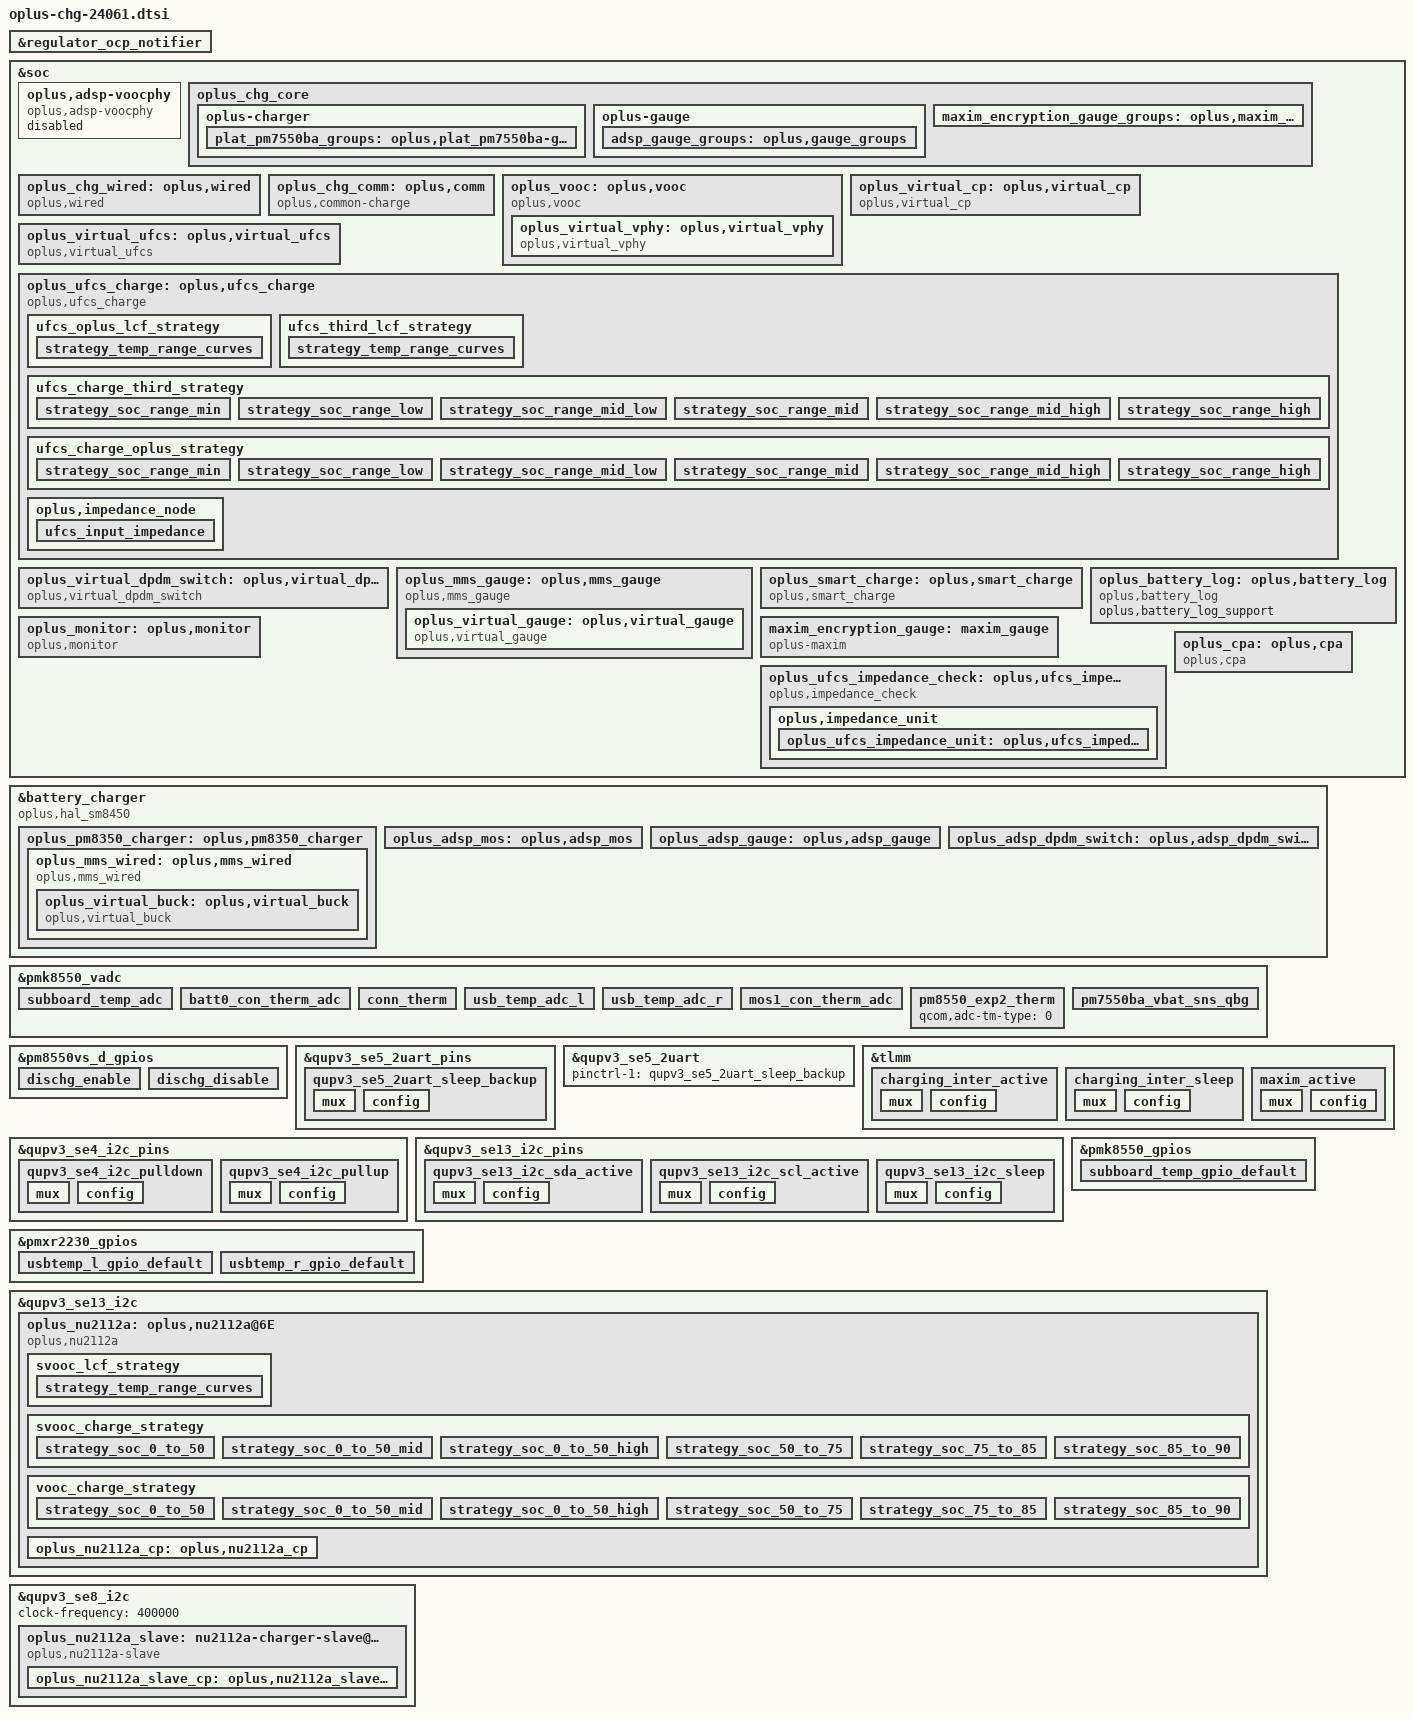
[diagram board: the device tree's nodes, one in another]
#include "oplus_chg.h"

&regulator_ocp_notifier {
	periph-1cb-supply = <0>;
	periph-1cc-supply = <0>;
	periph-1cd-supply = <0>;
	periph-4c1-supply = <0>;
	periph-4c3-supply = <0>;
};

&soc {
	oplus,adsp-voocphy {
		status = "disabled";
		compatible = "oplus,adsp-voocphy";
	};

	oplus_chg_core {
		oplus,chg_framework_v2;
		oplus,smart_charging_screenoff;
		oplus,chg_spec_version = <OPLUS_CHG_SPEC_VER_V3P7>;

		oplus-charger {
			plat_pm7550ba_groups: oplus,plat_pm7550ba-groups {
				functions = <
					OPLUS_IC_FUNC_INIT
					OPLUS_IC_FUNC_EXIT
					OPLUS_IC_FUNC_REG_DUMP
					OPLUS_IC_FUNC_SMT_TEST
					OPLUS_IC_FUNC_BUCK_INPUT_PRESENT
					OPLUS_IC_FUNC_BUCK_INPUT_SUSPEND
					OPLUS_IC_FUNC_BUCK_INPUT_IS_SUSPEND
					OPLUS_IC_FUNC_BUCK_OUTPUT_SUSPEND
					OPLUS_IC_FUNC_BUCK_OUTPUT_IS_SUSPEND
					OPLUS_IC_FUNC_BUCK_GET_CC_ORIENTATION
					OPLUS_IC_FUNC_BUCK_GET_CHARGER_TYPE
					OPLUS_IC_FUNC_BUCK_RERUN_BC12
					OPLUS_IC_FUNC_BUCK_QC_DETECT_ENABLE
					OPLUS_IC_FUNC_BUCK_SHIPMODE_ENABLE
					OPLUS_IC_FUNC_BUCK_SET_QC_CONFIG
					OPLUS_IC_FUNC_BUCK_SET_PD_CONFIG
					OPLUS_IC_FUNC_BACKUP_SOC
					OPLUS_IC_FUNC_GET_SHUTDOWN_SOC
					OPLUS_IC_FUNC_GET_TYPEC_MODE
					OPLUS_IC_FUNC_BUCK_SET_ICL
					OPLUS_IC_FUNC_BUCK_GET_ICL
					OPLUS_IC_FUNC_BUCK_SET_FCC
					OPLUS_IC_FUNC_BUCK_SET_FV
					OPLUS_IC_FUNC_BUCK_SET_ITERM
					OPLUS_IC_FUNC_BUCK_SET_RECHG_VOL
					OPLUS_IC_FUNC_BUCK_GET_INPUT_CURR
					OPLUS_IC_FUNC_BUCK_GET_INPUT_VOL
					OPLUS_IC_FUNC_GET_CHARGER_CYCLE
					OPLUS_IC_FUNC_OTG_BOOST_ENABLE
					OPLUS_IC_FUNC_BUCK_GET_VBUS_COLLAPSE_STATUS
					OPLUS_IC_FUNC_GET_OTG_ENABLE
					OPLUS_IC_FUNC_SET_OTG_SWITCH_STATUS
					OPLUS_IC_FUNC_GET_OTG_SWITCH_STATUS
					OPLUS_IC_FUNC_GET_OTG_ONLINE_STATUS
					OPLUS_IC_FUNC_BUCK_GET_HW_DETECT
					OPLUS_IC_FUNC_VOOCPHY_SET_MATCH_TEMP
					OPLUS_IC_FUNC_IS_OPLUS_SVID
					OPLUS_IC_FUNC_BUCK_GET_USB_BTB_TEMP
					OPLUS_IC_FUNC_BUCK_GET_BATT_BTB_TEMP
					OPLUS_IC_FUNC_SET_TYPEC_MODE
					OPLUS_IC_FUNC_GET_TYPEC_ROLE
				>;
				virqs = <
					OPLUS_IC_VIRQ_ERR
					OPLUS_IC_VIRQ_CC_DETECT
					OPLUS_IC_VIRQ_PLUGIN
					OPLUS_IC_VIRQ_CC_CHANGED
					OPLUS_IC_VIRQ_CHG_TYPE_CHANGE
					OPLUS_IC_VIRQ_SVID
					OPLUS_IC_VIRQ_OTG_ENABLE
				>;
			};
		};

		oplus-gauge {
			adsp_gauge_groups: oplus,gauge_groups {
				functions = <
					OPLUS_IC_FUNC_INIT
					OPLUS_IC_FUNC_EXIT
					OPLUS_IC_FUNC_REG_DUMP
					OPLUS_IC_FUNC_SMT_TEST
					OPLUS_IC_FUNC_GAUGE_GET_BATT_VOL
					OPLUS_IC_FUNC_GAUGE_GET_BATT_MAX
					OPLUS_IC_FUNC_GAUGE_GET_BATT_MIN
					OPLUS_IC_FUNC_GAUGE_GET_BATT_CURR
					OPLUS_IC_FUNC_GAUGE_GET_BATT_TEMP
					OPLUS_IC_FUNC_GAUGE_GET_BATT_SOC
					OPLUS_IC_FUNC_GAUGE_GET_BATT_FCC
					OPLUS_IC_FUNC_GAUGE_GET_BATT_CC
					OPLUS_IC_FUNC_GAUGE_GET_BATT_RM
					OPLUS_IC_FUNC_GAUGE_GET_BATT_SOH
					OPLUS_IC_FUNC_GAUGE_GET_BATT_HMAC
					OPLUS_IC_FUNC_GAUGE_SET_BATT_FULL
					OPLUS_IC_FUNC_GAUGE_UPDATE_DOD0
					OPLUS_IC_FUNC_GAUGE_UPDATE_SOC_SMOOTH
					OPLUS_IC_FUNC_GAUGE_GET_CB_STATUS
					OPLUS_IC_FUNC_GAUGE_GET_BATT_NUM
					OPLUS_IC_FUNC_GAUGE_GET_DEVICE_TYPE
					OPLUS_IC_FUNC_GAUGE_GET_DEVICE_TYPE_FOR_VOOC
					OPLUS_IC_FUNC_GAUGE_GET_BATT_FCC
					OPLUS_IC_FUNC_GAUGE_UPDATE
					OPLUS_IC_FUNC_GAUGE_IS_SUSPEND
					OPLUS_IC_FUNC_GAUGE_GET_SUBBOARD_TEMP
					OPLUS_IC_FUNC_GAUGE_GET_BCC_PARMS
					OPLUS_IC_FUNC_GAUGE_GET_DEVICE_TYPE_FOR_BCC
					OPLUS_IC_FUNC_GAUGE_GET_DOD0
					OPLUS_IC_FUNC_GAUGE_GET_DOD0_PASSED_Q
					OPLUS_IC_FUNC_GAUGE_GET_QMAX
					OPLUS_IC_FUNC_GAUGE_GET_QMAX_PASSED_Q
				>;
				virqs = <
					OPLUS_IC_VIRQ_ERR
					OPLUS_IC_VIRQ_OFFLINE
					OPLUS_IC_VIRQ_RESUME
				>;
			};
		};

		maxim_encryption_gauge_groups: oplus,maxim_encryption_gauge_groups {
			functions = <
				OPLUS_IC_FUNC_INIT
				OPLUS_IC_FUNC_EXIT
				OPLUS_IC_FUNC_GAUGE_GET_BATT_AUTH
			>;
			virqs = <
				OPLUS_IC_VIRQ_ERR
			>;
		};
	};

	oplus_chg_wired: oplus,wired {
		compatible = "oplus,wired";
		oplus,vooc-support;

		oplus_spec,vbatt_pdqc_to_9v_thr = <5000>;
		oplus_spec,pd-iclmax-ma = <1500>;
		oplus_spec,qc-iclmax-ma = <1500>;
		oplus_spec,non-standard-ibatmax-ma = <1000>;
		oplus_spec,input-power-mw = <
			2500		/* OPLUS_WIRED_CHG_MODE_UNKNOWN */
			2500		/* OPLUS_WIRED_CHG_MODE_SDP */
			7500		/* OPLUS_WIRED_CHG_MODE_CDP */
			10000		/* OPLUS_WIRED_CHG_MODE_DCP */
			30000		/* OPLUS_WIRED_CHG_MODE_VOOC */
			13500		/* OPLUS_WIRED_CHG_MODE_QC */
			13500		/* OPLUS_WIRED_CHG_MODE_PD */
		>;
		oplus_spec,led_on-fccmax-ma = <0 1340 4000 4000 4000 4000 4000 1000 0>;
		oplus_spec,fccmax-ma-lv = <
			0 1555 2200 2200 2200 2200 2200 2200 0	/* OPLUS_WIRED_CHG_MODE_UNKNOWN */
			0 600  600  600  600  600  600  600  0	/* OPLUS_WIRED_CHG_MODE_SDP */
			0 1555 1600 1600 1600 1600 1600 1600 0	/* OPLUS_WIRED_CHG_MODE_CDP */
			0 1555 2200 2200 2200 2200 2200 2200 0	/* OPLUS_WIRED_CHG_MODE_DCP */
			0 1340 3600 3600 3600 3600 3600 2948 0	/* OPLUS_WIRED_CHG_MODE_VOOC */
			0 1555 3300 3300 3300 3300 3300 3300 0	/* OPLUS_WIRED_CHG_MODE_QC */
			0 1555 3300 3300 3300 3300 3300 3300 0	/* OPLUS_WIRED_CHG_MODE_PD */
		>;
		oplus_spec,fccmax-ma-hv = <
			0 1555 2200 2200 2200 2200 2200 2200 0	/* OPLUS_WIRED_CHG_MODE_UNKNOWN */
			0 600  600  600  600  600  600  600  0	/* OPLUS_WIRED_CHG_MODE_SDP */
			0 1555 1600 1600 1600 1600 1600 1600 0	/* OPLUS_WIRED_CHG_MODE_CDP */
			0 1555 2200 2200 2200 2200 2200 2200 0	/* OPLUS_WIRED_CHG_MODE_DCP */
			0 1340 3600 3600 3600 3600 3600 2948 0	/* OPLUS_WIRED_CHG_MODE_VOOC */
			0 1555 3300 3300 3300 3300 3300 3300 0	/* OPLUS_WIRED_CHG_MODE_QC */
			0 1555 3300 3300 3300 3300 3300 3300 0	/* OPLUS_WIRED_CHG_MODE_PD */
		>;

		oplus_spec,cool_down_pdqc_vol_mv = <9000 9000 9000>;
		oplus_spec,cool_down_pdqc_curr_ma = <1200 1500 1500>;
		oplus_spec,cool_down_vooc_curr_ma = <1200 1500 2000 2500 3000 3000>;
		oplus_spec,cool_down_normal_curr_ma = <1200 1500 2000>;

		oplus_spec,vbus_ov_thr_mv = <11000 11000>;
		oplus_spec,vbus_uv_thr_mv = <4300 4300>;

		/* first data is strategy used temp type */
		oplus,vooc_strategy_name = "cgcl";
		oplus,vooc_strategy_data = <OPLUS_STRATEGY_USE_BATT_TEMP
					    0   350 3000 1 0
					    330 370 3000 2 0
					    350 440 2200 2 1>;
	};

	oplus_chg_comm: oplus,comm {
		compatible = "oplus,common-charge";
		oplus_spec,batt-them-thr = <(-100) 0 50 120 160 350 450 530>;
		oplus_spec,iterm-ma = <144>;
		oplus_spec,fv-mv = <4470 4470 4470 4470 4470 4470 4470 4130 4130>;
		oplus_spec,sw-fv-mv = <4420 4420 4420 4420 4420 4420 4420 4080 4080>;
		oplus_spec,hw-fv-inc-mv = <0 18 18 18 18 18 18 18 0>;
		oplus_spec,sw-over-fv-mv = <4480 4480 4480 4480 4480 4480 4480 4140 4140>;
		oplus_spec,sw-over-fv-dec-mv = <8>;
		oplus_spec,non-standard-sw-fv-mv = <3930>;
		oplus_spec,non-standard-fv-mv = <3980>;
		oplus_spec,non-standard-hw-fv-inc-mv = <18>;
		oplus_spec,non-standard-sw-over-fv-mv = <3990>;
		oplus_spec,non-standard-vbatdet-mv = <3680>;
		oplus_spec,wired-vbatdet-mv = <0 4170 4270 4370 4370 4370 4370 4030 0>;
		/* oplus_spec,wls-vbatdet-mv = <0 3675 4235 4370 4370 4370 4030 0>; */
		oplus_spec,fcc-gear-thr-mv = <4180>;
		oplus_spec,vbatt-ov-thr-mv = <4600>;

		oplus_spec,full_pre_ffc_judge;
		oplus_spec,full-pre-ffc-mv = <4465>;
		oplus_spec,ffc-temp-thr = <120 200 350 400>;
		oplus_spec,wired-ffc-step-max = <2>;
		oplus_spec,wired-ffc-fv-mv = <4590 4590>;
		oplus_spec,wired-ffc-fv-cutoff-mv = <4565 4565 4565 4565 4565 4565>;

		oplus_spec,removed_bat_decidegc = <390>;

		oplus_spec,wired-ffc-fcc-ma = <1500 1500 1700
					       700  700  700>;
		oplus_spec,wired-ffc-fcc-cutoff-ma = <800 1100 1500
						      800 1100 1500>;

		/* 2s battery */
		oplus_spec,wired-aging-ffc-version = <AGING_FFC_V1>;
		oplus_spec,wired-aging-ffc-offset-mv = <15 30
							10 20>;
		oplus_spec,wired-aging-ffc-cycle-thr = <500 1000>;

		oplus_spec,wls-ffc-step-max = <2>;
		oplus_spec,wls-ffc-fv-mv = <4500 4500>;
		oplus_spec,wls-ffc-fv-cutoff-mv = <4445 4435>;
		oplus_spec,wls-ffc-icl-ma = <800 800
					     550  550>;
		oplus_spec,wls-ffc-fcc-ma = <550 550
					     350 350>;
		oplus_spec,wls-ffc-fcc-cutoff-ma = <400 400
						    200 200>;
		oplus_spec,vbat_uv_thr_mv = <3300>;
		oplus_spec,vbat_charging_uv_thr_mv = <3200>;

		/*If use subboard NTC as battery temp, config it as 20, otherwise 0 */
		oplus_spec,tbatt_power_off_cali_temp = <20>;
		oplus,vooc_show_ui_soc_decimal;
		oplus,ui_soc_decimal_speedmin = <20>;

		oplus,gauge_stuck_jump_support;
		oplus,gauge_stuck_threshold = <15>;
		oplus,gauge_stuck_time = <50>;

		oplus,smooth_switch;
		oplus,reserve_chg_soc = <3>;
		oplus,reserve_dis_soc = <3>;
	};

	oplus_vooc: oplus,vooc {
		compatible = "oplus,vooc";
		oplus,vooc_ic = <&oplus_virtual_vphy>;

		oplus_spec,vooc_soc_range = <50 75 85>;
		oplus_spec,vooc_temp_range = <50 120 180 350 450>;

		oplus,vooc_data_width = <7>;
		oplus,vooc_curr_max = <CP_CURR_LIMIT_7BIT_15_0A>;  /* 80W: 11V 7.3A(IBUS *2) */
		oplus,vooc_project = <7>;  /* 80W, 11V 7.3A */
		oplus,vooc_curr_table_type = <VOOC_CP_CURR_TABLE>;
		oplus,vooc_power_max_w = <80>;
		oplus,voocphy_support = <3>; /* AP_DUAL_CP_VOOCPHY */
		oplus,support_fake_vooc_check;
		oplus,subboard_ntc_abnormal_current = <4000>;

		oplus,smart_chg_bcc_support;

		oplus,abnormal_adapter_current = <CP_CURR_LIMIT_7BIT_15_0A CP_CURR_LIMIT_7BIT_15_0A
						CP_CURR_LIMIT_7BIT_12_6A CP_CURR_LIMIT_7BIT_12_6A
						CP_CURR_LIMIT_7BIT_10_0A CP_CURR_LIMIT_7BIT_10_0A
						CP_CURR_LIMIT_7BIT_8_0A CP_CURR_LIMIT_7BIT_8_0A
						CP_CURR_LIMIT_7BIT_6_0A CP_CURR_LIMIT_7BIT_6_0A>;

		oplus,abnormal_over_80w_adapter_current = <CP_CURR_LIMIT_7BIT_15_0A CP_CURR_LIMIT_7BIT_15_0A
						CP_CURR_LIMIT_7BIT_14_0A CP_CURR_LIMIT_7BIT_14_0A
						CP_CURR_LIMIT_7BIT_12_0A CP_CURR_LIMIT_7BIT_12_0A
						CP_CURR_LIMIT_7BIT_10_0A CP_CURR_LIMIT_7BIT_10_0A
						CP_CURR_LIMIT_7BIT_8_0A  CP_CURR_LIMIT_7BIT_8_0A
						CP_CURR_LIMIT_7BIT_6_0A  CP_CURR_LIMIT_7BIT_6_0A
						CP_CURR_LIMIT_7BIT_4_0A CP_CURR_LIMIT_7BIT_4_0A>;

		/* first data is strategy used temp type */
		oplus,general_strategy_name = "cgcl";
		oplus,general_strategy_data = < OPLUS_STRATEGY_USE_SHELL_TEMP
						0   385 CP_CURR_LIMIT_7BIT_15_0A 1 0
						375 395 CP_CURR_LIMIT_7BIT_12_6A 2 0
						385 420 CP_CURR_LIMIT_7BIT_8_0A 3 1
						410 440 CP_CURR_LIMIT_7BIT_6_0A 3 2 >;

		oplus_virtual_vphy: oplus,virtual_vphy {
			compatible = "oplus,virtual_vphy";
			oplus,vphy_ic = <&oplus_nu2112a>;
			oplus,dpdm_switch_ic = <&oplus_virtual_dpdm_switch>;

			oplus,ic_type = <OPLUS_CHG_IC_VIRTUAL_VPHY>;
			oplus,ic_index = <0>;
		};
	};

	oplus_virtual_cp: oplus,virtual_cp {
		compatible = "oplus,virtual_cp";

		oplus,ic_type = <OPLUS_CHG_IC_VIRTUAL_CP>;
		oplus,ic_index = <0>;

		oplus,cp_ic = <&oplus_nu2112a_cp &oplus_nu2112a_slave_cp>;
		oplus,input_curr_max_ma = <3000 0>;

		oplus,cp_ic_connect = <OPLUS_CHG_IC_CONNECT_PARALLEL>;
		oplus,main_cp = <0>;

		oplus,reg_proc_node;
	};

	oplus_virtual_ufcs: oplus,virtual_ufcs {
		compatible = "oplus,virtual_ufcs";

		oplus,ic_type = <OPLUS_CHG_IC_VIRTUAL_UFCS>;
		oplus,ic_index = <0>;
	};

	oplus_ufcs_charge: oplus,ufcs_charge {
		compatible = "oplus,ufcs_charge";
		oplus,ufcs_ic = <&oplus_virtual_ufcs>;
		oplus,cp_ic = <&oplus_virtual_cp>;
		oplus,dpdm_switch_ic = <&oplus_virtual_dpdm_switch>;
		oplus,impedance_unit = <&oplus_ufcs_impedance_unit>;

		oplus,target_vbus_mv = <11000>;
		oplus,curr_max_ma = <3000>;
                oplus,high_imp_compensation_setting_mv = <100>;

		oplus,ufcs_warm_allow_vol = <4000>;
		oplus,ufcs_warm_allow_soc = <50>;
		oplus,ufcs_strategy_normal_current = <3000>;
		oplus,ufcs_over_high_or_low_current = <3000>;
		oplus,ufcs_timeout_third = <10800>;
		oplus,ufcs_timeout_oplus = <10800>;
		oplus,ufcs_ibat_over_third = <7000>;
		oplus,ufcs_ibat_over_oplus = <7000>;
		oplus,ufcs_full_cool_sw_vbat = <4470>;
		oplus,ufcs_full_normal_sw_vbat = <4470>;
		oplus,ufcs_full_normal_hw_vbat = <4480>;
		oplus,ufcs_full_ffc_vbat = <4520>;
		oplus,ufcs_full_warm_vbat = <4130>;
		oplus,ufcs_full_cool_sw_vbat_third = <4470>;
		oplus,ufcs_full_normal_sw_vbat_third= <4470>;
		oplus,ufcs_full_normal_hw_vbat_third = <4480>;
		oplus,ufcs_current_change_timeout = <100>;
		oplus,ufcs_strategy_batt_high_temp = <410 420 430 400 410 420>;
		oplus,ufcs_strategy_high_current = <3000 3000 2000 3000 3000 2000>;
		oplus,ufcs_little_cool_high_temp = <200>;
		oplus,curve_strategy_name = "pps_ufcs_curve_v2";
		oplus_spec,ufcs_high_soc = <95>;
		oplus,ufcs_charge_strategy_soc = <0 20 35 55 75 85 95>;
		oplus,ufcs_charge_strategy_temp = <0 50 120 160 350 440 510>;

		ufcs_oplus_lcf_strategy {
			oplus,temp_type = <OPLUS_STRATEGY_USE_SHELL_TEMP>;
			oplus,temp_range = <0 50 120 160 200 350 430>;
			strategy_temp_range_curves {
				strategy_temp_range_t0 =	<500 4470 0
								 450 4460 0
								 400 4450 0
								 350 4440 0
								 300 4430 1>;
				strategy_temp_range_t1 =	<700 4470 0
								 650 4460 0
								 600 4450 0
								 550 4440 0
								 500 4430 1>;
				strategy_temp_range_t2 =	<950 4570 0
								 850 4565 0
								 750 4550 0
								 650 4540 0
								 550 4530 1>;
				strategy_temp_range_t3 =	<1250 4570 0
								 1150 4565 0
								 1050 4550 0
								 950  4540 0
								 850  4530 1>;
				strategy_temp_range_t4 =	<1250 4570 0
								 1150 4565 0
								 1050 4550 0
								 950  4540 0
								 850  4530 1>;
				strategy_temp_range_t5 =	<1650 4570 0
								 1550 4565 0
								 1450 4550 0
								 1350 4540 0
								 1250 4530 1>;
			};
		};
		ufcs_third_lcf_strategy {
			oplus,temp_type = <OPLUS_STRATEGY_USE_SHELL_TEMP>;
			oplus,temp_range = <0 50 120 160 200 350 430>;
			strategy_temp_range_curves {
				strategy_temp_range_t0 =	<500 4470 0
								 450 4460 0
								 400 4450 0
								 350 4440 0
								 300 4430 1>;
				strategy_temp_range_t1 =	<700 4470 0
								 650 4460 0
								 600 4450 0
								 550 4440 0
								 500 4430 1>;
				strategy_temp_range_t2 =	<950 4570 0
								 850 4565 0
								 750 4550 0
								 650 4540 0
								 550 4530 1>;
				strategy_temp_range_t3 =	<1250 4570 0
								 1150 4565 0
								 1050 4550 0
								 950  4540 0
								 850  4530 1>;
				strategy_temp_range_t4 =	<1250 4570 0
								 1150 4565 0
								 1050 4550 0
								 950  4540 0
								 850  4530 1>;
				strategy_temp_range_t5 =	<1650 4570 0
								 1550 4565 0
								 1450 4550 0
								 1350 4540 0
								 1250 4530 1>;
			};
		};

		ufcs_charge_third_strategy {
			oplus,temp_type = <OPLUS_STRATEGY_USE_SHELL_TEMP>;
			oplus,soc_range = <0 20 35 55 75 85 95>;
			oplus,temp_range = <0 50 120 160 200 350 440 510>;

			strategy_soc_range_min {
				strategy_temp_little_cold =	<11000 4150 3000 0 0
								11000 4460 2900 0 0
								11000 4460 2500 0 0
								11000 4460 2300 0 0
								11000 4460 2000 0 0
								11000 4460 1500 0 0
								11000 4470 1000 1 0>;
				strategy_temp_cool =		<11000 4460 3000 0 0
								11000 4460 2500 0 0
								11000 4460 2300 0 0
								11000 4460 2000 0 0
								11000 4460 1500 0 0
								11000 4470 1000 1 0>;
				strategy_temp_little_cool =	<11000 4460 3000 0 0
								11000 4460 2500 0 0
								11000 4460 2000 0 0
								11000 4460 1500 0 0
								11000 4470 1000 1 0>;
				strategy_temp_little_cool_high =	<11000 4460 3000 0 0
								11000 4460 2500 0 0
								11000 4460 2000 0 0
								11000 4460 1500 0 0
								11000 4470 1000 1 0>;
				strategy_temp_normal_low =	<11000 4460 3000 0 0
								11000 4460 2500 0 0
								11000 4460 2000 0 0
								11000 4460 1500 0 0
								11000 4470 1000 1 0>;
				strategy_temp_normal_high =	<11000 4460 3000 0 0
								11000 4460 2500 0 0
								11000 4460 2000 0 0
								11000 4460 1500 0 0
								11000 4470 1000 1 0>;
				strategy_temp_warm =		<11000 4120 1000 1 0>;
			};
			strategy_soc_range_low {
				strategy_temp_little_cold =	<11000 4150 3000 0 0
								11000 4460 2900 0 0
								11000 4460 2500 0 0
								11000 4460 2300 0 0
								11000 4460 2000 0 0
								11000 4460 1500 0 0
								11000 4470 1000 1 0>;
				strategy_temp_cool =		<11000 4460 3000 0 0
								11000 4460 2500 0 0
								11000 4460 2300 0 0
								11000 4460 2000 0 0
								11000 4460 1500 0 0
								11000 4470 1000 1 0>;
				strategy_temp_little_cool =	<11000 4460 3000 0 0
								11000 4460 2500 0 0
								11000 4460 2000 0 0
								11000 4460 1500 0 0
								11000 4470 1000 1 0>;
				strategy_temp_little_cool_high =	<11000 4460 3000 0 0
								11000 4460 2500 0 0
								11000 4460 2000 0 0
								11000 4460 1500 0 0
								11000 4470 1000 1 0>;
				strategy_temp_normal_low =	<11000 4460 3000 0 0
								11000 4460 2500 0 0
								11000 4460 2000 0 0
								11000 4460 1500 0 0
								11000 4470 1000 1 0>;
				strategy_temp_normal_high =	<11000 4460 3000 0 0
								11000 4460 2500 0 0
								11000 4460 2000 0 0
								11000 4460 1500 0 0
								11000 4470 1000 1 0>;
				strategy_temp_warm =		<11000 4120 1000 1 0>;
			};
			strategy_soc_range_mid_low {
				strategy_temp_little_cold =	<11000 4460 2000 0 0
								11000 4460 1500 0 0
								11000 4470 1000 1 0>;
				strategy_temp_cool =		<11000 4460 2500 0 0
								11000 4460 2300 0 0
								11000 4460 2000 0 0
								11000 4460 1500 0 0
								11000 4470 1000 1 0>;
				strategy_temp_little_cool =	<11000 4460 3000 0 0
								11000 4460 2500 0 0
								11000 4460 2000 0 0
								11000 4460 1500 0 0
								11000 4470 1000 1 0>;
				strategy_temp_little_cool_high =	<11000 4460 3000 0 0
								11000 4460 2500 0 0
								11000 4460 2000 0 0
								11000 4460 1500 0 0
								11000 4470 1000 1 0>;
				strategy_temp_normal_low =	<11000 4460 3000 0 0
								11000 4460 2500 0 0
								11000 4460 2000 0 0
								11000 4460 1500 0 0
								11000 4470 1000 1 0>;
				strategy_temp_normal_high =	<11000 4460 3000 0 0
								11000 4460 2500 0 0
								11000 4460 2000 0 0
								11000 4460 1500 0 0
								11000 4470 1000 1 0>;
				strategy_temp_warm =		<11000 4120 1000 1 0>;
			};
			strategy_soc_range_mid {
				strategy_temp_little_cold =	<11000 4460 1500 0 0
								11000 4470 1000 1 0>;
				strategy_temp_cool =		<11000 4460 1500 0 0
								11000 4470 1000 1 0>;
				strategy_temp_little_cool =	<11000 4460 2000 0 0
								11000 4460 1500 0 0
								11000 4470 1000 1 0>;
				strategy_temp_little_cool_high =	<11000 4460 2000 0 0
								11000 4460 1500 0 0
								11000 4470 1000 1 0>;
				strategy_temp_normal_low =	<11000 4460 2000 0 0
								11000 4460 1500 0 0
								11000 4470 1000 1 0>;
				strategy_temp_normal_high =	<11000 4460 2500 0 0
								11000 4460 2000 0 0
								11000 4460 1500 0 0
								11000 4470 1000 1 0>;
				strategy_temp_warm =		<11000 4120 1000 1 0>;
			};
			strategy_soc_range_mid_high {
				strategy_temp_little_cold =	<11000 4470 1000 1 0>;
				strategy_temp_cool =		<11000 4470 1000 1 0>;
				strategy_temp_little_cool =	<11000 4460 1500 0 0
								11000 4470 1000 1 0>;
				strategy_temp_little_cool_high =	<11000 4460 1500 0 0
								11000 4470 1000 1 0>;
				strategy_temp_normal_low =	<11000 4460 1500 0 0
								11000 4470 1000 1 0>;
				strategy_temp_normal_high =	<11000 4460 1500 0 0
								11000 4470 1000 1 0>;
				strategy_temp_warm =		<11000 4120 1000 1 0>;
			};
			strategy_soc_range_high {
				strategy_temp_little_cold =	<11000 4470 1000 1 0>;
				strategy_temp_cool =		<11000 4470 1000 1 0>;
				strategy_temp_little_cool =	<11000 4470 1000 1 0>;
				strategy_temp_little_cool_high =	<11000 4470 1000 1 0>;
				strategy_temp_normal_low =	<11000 4470 1000 1 0>;
				strategy_temp_normal_high =	<11000 4470 1000 1 0>;
				strategy_temp_warm =		<11000 4120 1000 1 0>;
			};
		};

		ufcs_charge_oplus_strategy {
			oplus,temp_type = <OPLUS_STRATEGY_USE_SHELL_TEMP>;
			oplus,soc_range = <0 20 35 55 75 85 95>;
			oplus,temp_range = <0 50 120 160 200 350 440 510>;

			strategy_soc_range_min {
				strategy_temp_little_cold =	<11000 4150 3000 0 0
								11000 4460 2900 0 0
								11000 4460 2500 0 0
								11000 4460 2300 0 0
								11000 4460 2000 0 0
								11000 4460 1500 0 0
								11000 4470 1000 1 0>;
				strategy_temp_cool =		<11000 4460 3000 0 0
								11000 4460 2500 0 0
								11000 4460 2300 0 0
								11000 4460 2000 0 0
								11000 4460 1500 0 0
								11000 4470 1000 1 0>;
				strategy_temp_little_cool =	<11000 4460 3000 0 0
								11000 4460 2500 0 0
								11000 4460 2000 0 0
								11000 4460 1500 0 0
								11000 4470 1000 1 0>;
				strategy_temp_little_cool_high =	<11000 4460 3000 0 0
								11000 4460 2500 0 0
								11000 4460 2000 0 0
								11000 4460 1500 0 0
								11000 4470 1000 1 0>;
				strategy_temp_normal_low =	<11000 4460 3000 0 0
								11000 4460 2500 0 0
								11000 4460 2000 0 0
								11000 4460 1500 0 0
								11000 4470 1000 1 0>;
				strategy_temp_normal_high =	<11000 4460 3000 0 0
								11000 4460 2500 0 0
								11000 4460 2000 0 0
								11000 4460 1500 0 0
								11000 4470 1000 1 0>;
				strategy_temp_warm =		<11000 4120 1000 1 0>;
			};
			strategy_soc_range_low {
				strategy_temp_little_cold =	<11000 4150 3000 0 0
								11000 4460 2900 0 0
								11000 4460 2500 0 0
								11000 4460 2300 0 0
								11000 4460 2000 0 0
								11000 4460 1500 0 0
								11000 4470 1000 1 0>;
				strategy_temp_cool =		<11000 4460 3000 0 0
								11000 4460 2500 0 0
								11000 4460 2300 0 0
								11000 4460 2000 0 0
								11000 4460 1500 0 0
								11000 4470 1000 1 0>;
				strategy_temp_little_cool =	<11000 4460 3000 0 0
								11000 4460 2500 0 0
								11000 4460 2000 0 0
								11000 4460 1500 0 0
								11000 4470 1000 1 0>;
				strategy_temp_little_cool_high =	<11000 4460 3000 0 0
								11000 4460 2500 0 0
								11000 4460 2000 0 0
								11000 4460 1500 0 0
								11000 4470 1000 1 0>;
				strategy_temp_normal_low =	<11000 4460 3000 0 0
								11000 4460 2500 0 0
								11000 4460 2000 0 0
								11000 4460 1500 0 0
								11000 4470 1000 1 0>;
				strategy_temp_normal_high =	<11000 4460 3000 0 0
								11000 4460 2500 0 0
								11000 4460 2000 0 0
								11000 4460 1500 0 0
								11000 4470 1000 1 0>;
				strategy_temp_warm =		<11000 4120 1000 1 0>;
			};
			strategy_soc_range_mid_low {
				strategy_temp_little_cold =	<11000 4460 2000 0 0
								11000 4460 1500 0 0
								11000 4470 1000 1 0>;
				strategy_temp_cool =		<11000 4460 2500 0 0
								11000 4460 2300 0 0
								11000 4460 2000 0 0
								11000 4460 1500 0 0
								11000 4470 1000 1 0>;
				strategy_temp_little_cool =	<11000 4460 3000 0 0
								11000 4460 2500 0 0
								11000 4460 2000 0 0
								11000 4460 1500 0 0
								11000 4470 1000 1 0>;
				strategy_temp_little_cool_high =	<11000 4460 3000 0 0
								11000 4460 2500 0 0
								11000 4460 2000 0 0
								11000 4460 1500 0 0
								11000 4470 1000 1 0>;
				strategy_temp_normal_low =	<11000 4460 3000 0 0
								11000 4460 2500 0 0
								11000 4460 2000 0 0
								11000 4460 1500 0 0
								11000 4470 1000 1 0>;
				strategy_temp_normal_high =	<11000 4460 3000 0 0
								11000 4460 2500 0 0
								11000 4460 2000 0 0
								11000 4460 1500 0 0
								11000 4470 1000 1 0>;
				strategy_temp_warm =		<11000 4120 1000 1 0>;
			};
			strategy_soc_range_mid {
				strategy_temp_little_cold =	<11000 4460 1500 0 0
								11000 4470 1000 1 0>;
				strategy_temp_cool =		<11000 4460 1500 0 0
								11000 4470 1000 1 0>;
				strategy_temp_little_cool =	<11000 4460 2000 0 0
								11000 4460 1500 0 0
								11000 4470 1000 1 0>;
				strategy_temp_little_cool_high =	<11000 4460 2000 0 0
								11000 4460 1500 0 0
								11000 4470 1000 1 0>;
				strategy_temp_normal_low =	<11000 4460 2000 0 0
								11000 4460 1500 0 0
								11000 4470 1000 1 0>;
				strategy_temp_normal_high =	<11000 4460 2500 0 0
								11000 4460 2000 0 0
								11000 4460 1500 0 0
								11000 4470 1000 1 0>;
				strategy_temp_warm =		<11000 4120 1000 1 0>;
			};
			strategy_soc_range_mid_high {
				strategy_temp_little_cold =	<11000 4470 1000 1 0>;
				strategy_temp_cool =		<11000 4470 1000 1 0>;
				strategy_temp_little_cool =	<11000 4460 1500 0 0
								11000 4470 1000 1 0>;
				strategy_temp_little_cool_high =	<11000 4460 1500 0 0
								11000 4470 1000 1 0>;
				strategy_temp_normal_low =	<11000 4460 1500 0 0
								11000 4470 1000 1 0>;
				strategy_temp_normal_high =	<11000 4460 1500 0 0
								11000 4470 1000 1 0>;
				strategy_temp_warm =		<11000 4120 1000 1 0>;
			};
			strategy_soc_range_high {
				strategy_temp_little_cold =	<11000 4470 1000 1 0>;
				strategy_temp_cool =		<11000 4470 1000 1 0>;
				strategy_temp_little_cool =	<11000 4470 1000 1 0>;
				strategy_temp_little_cool_high =	<11000 4470 1000 1 0>;
				strategy_temp_normal_low =	<11000 4470 1000 1 0>;
				strategy_temp_normal_high =	<11000 4470 1000 1 0>;
				strategy_temp_warm =		<11000 4120 1000 1 0>;
			};
		};

		oplus,impedance_node {
			ufcs_input_impedance: ufcs_input_impedance {
				node_name = "ufcs_input";
				default_impedance_mohm = <95>;
				default_curr_ma = <3000>;
				current_drop_table = <
					130  8000
					190  5000
					250  4000
					340  3000
					380  2000
					480  0
				>;
			};
		};
	};

	oplus_virtual_dpdm_switch: oplus,virtual_dpdm_switch {
		compatible = "oplus,virtual_dpdm_switch";
		oplus,ic_type = <OPLUS_CHG_IC_MISC>;
		oplus,ic_index = <0>;
		oplus,use_audio_switch;
	};

	oplus_mms_gauge: oplus,mms_gauge {
		compatible = "oplus,mms_gauge";
		oplus,gauge_ic = <&oplus_virtual_gauge>;
		oplus,voocphy_ic = <&oplus_virtual_vphy>;
		oplus,topic-update-interval = <5000>;
		oplus,support_subboard_ntc;

		oplus_virtual_gauge: oplus,virtual_gauge {
			compatible = "oplus,virtual_gauge";
			oplus,gauge_ic = <&oplus_adsp_gauge &maxim_encryption_gauge>;
			oplus,gauge_ic_index = <0 1>;
			oplus,gauge_ic_func_group =  <&adsp_gauge_groups &maxim_encryption_gauge_groups>;
			oplus,batt_capacity_mah = <6000>;
			oplus,ic_type = <OPLUS_CHG_IC_VIRTUAL_GAUGE>;
			oplus,ic_index = <0>;
		};
	};

	oplus_smart_charge: oplus,smart_charge {
		compatible = "oplus,smart_charge";
		//oplus,quick_mode_gain_support;
		/* TODO: only supported in the project >= 100W. */
	};

	oplus_battery_log: oplus,battery_log {
		compatible = "oplus,battery_log";
		oplus,battery_log_support;
	};

	oplus_monitor: oplus,monitor {
		compatible = "oplus,monitor";
		oplus,topic-update-interval = <60000>;
		track,fast_chg_break_t_thd = <1400>;
		track,general_chg_break_t_thd = <300>;
		track,voocphy_type = <2>;
		track,wired_max_power = <80000>;
		track,wired_fast_chg_scheme = <1>;
	};
};



&battery_charger {
	compatible = "oplus,hal_sm8450";

	qcom,pmic_ftm_vph = "/sys/bus/spmi/drivers/pmic-spmi/0-00/c42d000.qcom,spmi:qcom,pmk8550@0:vadc@9000/iio:device0/in_voltage_pm7550ba_vph_pwr_input";
	qcom,pmic_ftm_vbat = "/sys/bus/spmi/drivers/pmic-spmi/0-00/c42d000.qcom,spmi:qcom,pmk8550@0:vadc@9000/iio:device0/in_voltage_pm7550ba_vbat_sns_qbg_input";

	pinctrl-names = "subboard_temp_gpio_default";
	pinctrl-0 = <&subboard_temp_gpio_default>;

	//oplus,voocphy_bidirect_cp_support;
	oplus,chg_ops = "plat-pmic";
	oplus,otg_boost_src = <0>; /* 0:plat_pmic 1:external */
	oplus,batt_num = <1>;
	oplus,otg_scheme = <0>; /* 0:cid 1:ccdetect_gpio 2:switch */
	oplus,ic_type = <OPLUS_CHG_IC_BUCK>;
	oplus,ic_index = <0>;
	io-channels = <&pmk8550_vadc PMK8550_ADC5_GEN3_AMUX_THM3_GPIO2_100K_PU>,
		      <&pmk8550_vadc PMK8550_ADC5_GEN3_AMUX_THM2_GPIO1_100K_PU>,
		      <&pmk8550_vadc PM7550BA_ADC5_GEN3_AMUX_THM6_GPIO6_100K_PU>,
		      <&pmk8550_vadc PM7550BA_ADC5_GEN3_AMUX_THM4_USB_THERM_100K_PU>;

	io-channel-names = "mos1_con_therm_adc",
			   "subboard_temp_adc",
			   "batt0_con_therm_adc",
			   "conn_therm";

	oplus_pm8350_charger: oplus,pm8350_charger {
		oplus,ic_type = <OPLUS_CHG_IC_BUCK>;
		oplus,ic_index = <0>;

		oplus_mms_wired: oplus,mms_wired {
			compatible = "oplus,mms_wired";
			oplus,buck_ic = <&oplus_virtual_buck>;
			oplus,voocphy_ic = <&oplus_virtual_vphy>;
			oplus,usbtemp_batttemp_gap = <10>;
			oplus,adc_info_name = "855";
			oplus,topic-update-interval = <5000>;

			oplus,support_usbtemp_protect_v2;
			oplus_spec,usbtemp_batt_temp_low = <50>;
			oplus_spec,usbtemp_batt_temp_high = <50>;
			oplus_spec,usbtemp_ntc_temp_low = <57>;
			oplus_spec,usbtemp_ntc_temp_high = <69>;
			oplus_spec,usbtemp_temp_gap_low_with_batt_temp = <7>;
			oplus_spec,usbtemp_temp_gap_high_with_batt_temp = <12>;
			oplus_spec,usbtemp_temp_gap_low_without_batt_temp = <12>;
			oplus_spec,usbtemp_temp_gap_high_without_batt_temp = <24>;
			oplus_spec,usbtemp_rise_fast_temp_low = <3>;
			oplus_spec,usbtemp_rise_fast_temp_high = <3>;
			oplus_spec,usbtemp_rise_fast_temp_count_low = <30>;
			oplus_spec,usbtemp_rise_fast_temp_count_high = <20>;
			oplus_spec,usbtemp_cool_down_ntc_low = <54>;
			oplus_spec,usbtemp_cool_down_ntc_high = <65>;
			oplus_spec,usbtemp_cool_down_gap_low = <12>;
			oplus_spec,usbtemp_cool_down_gap_high = <20>;
			oplus_spec,usbtemp_cool_down_recover_ntc_low = <48>;
			oplus_spec,usbtemp_cool_down_recover_ntc_high = <60>;
			oplus_spec,usbtemp_cool_down_recover_gap_low = <6>;
			oplus_spec,usbtemp_cool_down_recover_gap_high = <15>;

		oplus_virtual_buck: oplus,virtual_buck {
			compatible = "oplus,virtual_buck";
			oplus,buck_ic = <&oplus_pm8350_charger>;
			oplus,buck_ic_index = <0>;
			oplus,buck_ic_connect = <OPLUS_CHG_IC_CONNECT_PARALLEL>;
			oplus,main_charger = <0>;
			oplus,buck_ic_current_ratio = <100>;
			oplus,buck_ic_func_group = <&plat_pm7550ba_groups>;

			oplus,ic_type = <OPLUS_CHG_IC_VIRTUAL_BUCK>;
			oplus,ic_index = <0>;

			oplus,uart_tx-gpio = <&tlmm 22 0x00>;
			oplus,uart_rx-gpio = <&tlmm 23 0x00>;

			oplus,dischg-gpio = <&pm8550vs_d_gpios 4 0x00>;
			//oplus,ship-gpio = <&tlmm 146 0x00>;
			pinctrl-names = "usbtemp_l_gpio_default", "usbtemp_r_gpio_default", /* TODO */
					"dischg_enable", "dischg_disable";
			pinctrl-0 = <&usbtemp_l_gpio_default>;
			pinctrl-1 = <&usbtemp_r_gpio_default>;
			pinctrl-2 = <&dischg_enable>;
			pinctrl-3 = <&dischg_disable>;

			io-channels = <&pmk8550_vadc PMXR2230_ADC5_GEN3_AMUX1_GPIO3_100K_PU>,
				      <&pmk8550_vadc PMXR2230_ADC5_GEN3_AMUX2_GPIO4_100K_PU>;
			io-channel-names = "usb_temp_adc_l",
					   "usb_temp_adc_r";
			};
		};
	};

	oplus_adsp_mos: oplus,adsp_mos {
		oplus,ic_type = <OPLUS_CHG_IC_CP>;
		oplus,ic_index = <0>;
	};

	oplus_adsp_gauge: oplus,adsp_gauge {
		oplus,ic_type = <OPLUS_CHG_IC_GAUGE>;
		oplus,ic_index = <0>;
	};

	oplus_adsp_dpdm_switch: oplus,adsp_dpdm_switch {
		oplus,ic_type = <OPLUS_CHG_IC_MISC>;
		oplus,ic_index = <0>;
	};
};

&pmk8550_vadc {
	subboard_temp_adc {
		reg = <PMK8550_ADC5_GEN3_AMUX_THM2_GPIO1_100K_PU>;
		label = "subboard_temp_adc";
		qcom,pre-scaling = <1 1>;
		qcom,ratiometric;
		qcom,hw-settle-time = <200>;
		qcom,scale-fn-type = <OPLUS_ADC_SCALE_HW_CALIB_DEFAULT>;
	};

	batt0_con_therm_adc {
		reg = <PM7550BA_ADC5_GEN3_AMUX_THM6_GPIO6_100K_PU>;
                label = "batt0_con_therm_adc";
                qcom,pre-scaling = <1 1>;
                qcom,ratiometric;
                qcom,hw-settle-time = <200>;
                qcom,scale-fn-type = <OPLUS_ADC_SCALE_HW_CALIB_DEFAULT>;
	};

	conn_therm {
		reg = <PM7550BA_ADC5_GEN3_AMUX_THM4_USB_THERM_100K_PU>;
                label = "conn_therm";
                qcom,pre-scaling = <1 1>;
                qcom,ratiometric;
                qcom,hw-settle-time = <200>;
                qcom,scale-fn-type = <OPLUS_ADC_SCALE_HW_CALIB_DEFAULT>;
	};

	usb_temp_adc_l {
		reg = <PMXR2230_ADC5_GEN3_AMUX1_GPIO3_100K_PU>;
                label = "usb_temp_adc_l";
                qcom,pre-scaling = <1 1>;
                qcom,ratiometric;
                qcom,hw-settle-time = <200>;
                qcom,scale-fn-type = <OPLUS_ADC_SCALE_HW_CALIB_DEFAULT>;
	};

	usb_temp_adc_r{
		reg = <PMXR2230_ADC5_GEN3_AMUX2_GPIO4_100K_PU>;
                label = "usb_supplementary_temp_adc ";
                qcom,pre-scaling = <1 1>;
                qcom,ratiometric;
                qcom,hw-settle-time = <200>;
                qcom,scale-fn-type = <OPLUS_ADC_SCALE_HW_CALIB_DEFAULT>;
	};

	/* TODO: the mos themperature is used by which? */
	mos1_con_therm_adc {
		reg = <PMK8550_ADC5_GEN3_AMUX_THM3_GPIO2_100K_PU>;
                label = "mos1_con_therm_adc";
                qcom,pre-scaling = <1 1>;
                qcom,ratiometric;
                qcom,hw-settle-time = <200>;
                qcom,scale-fn-type = <OPLUS_ADC_SCALE_HW_CALIB_DEFAULT>;
	};

	/* disable the pm8550_exp2_therm to fix the usb_temp_adc init failed! */
	pm8550_exp2_therm {
		qcom,adc-tm-type = <0>;
	};

	pm7550ba_vbat_sns_qbg {
		reg = <PM7550BA_ADC5_GEN3_VBAT_SNS_QBG>;
		label = "pm7550ba_vbat_sns_qbg";
		qcom,pre-scaling = <1 3>;
	};
};

&pm8550vs_d_gpios {
	dischg_enable: dischg_enable {
		pins = "gpio4";
		function = "normal";
		bias-disable;
		power-source = <0>;
		output-high;
		qcom,drive-strength = <2>;
	};

	dischg_disable: dischg_disable {
		pins = "gpio4";
		function = "normal";
		bias-disable;
		power-source = <0>;
		output-low;
		qcom,drive-strength = <2>;
	};
};

&qupv3_se5_2uart_pins {
	qupv3_se5_2uart_sleep_backup:qupv3_se5_2uart_sleep_backup {
 		mux {
			pins = "gpio22", "gpio23";
			function = "gpio";
		};

		config {
			pins = "gpio22", "gpio23";
			drive-strength = <2>;
			bias-disable;
			input-enable;
		};
	};
};

&qupv3_se5_2uart {
	pinctrl-1 = <&qupv3_se5_2uart_sleep_backup>;
	status = "ok";
};

&tlmm {
	charging_inter_active: charging_inter_active {
		mux {
			pins = "gpio51";
			function = "gpio";
		};
		config {
			pins = "gpio51";
			bias-pull-up; /* NO pull */
			drive-strength = <2>; /* 2 MA */
			input-enable;
		};
	};

	charging_inter_sleep: charging_inter_sleep {
		mux {
			pins = "gpio51"; /* nu2112a_INT*/
			function = "gpio";
		};
		config {
			pins = "gpio51";
			drive-strength = <2>; /* 2 MA */
		};
	};

	maxim_active: maxim_active {
		mux {
			pins = "gpio146";
			function = "gpio";
		};

		config {
			pins = "gpio146";
			bias-pull-up;
			drive-strength = <16>;
		};
	};
};

&soc {
	maxim_encryption_gauge: maxim_gauge {
		status = "ok";
		compatible = "oplus-maxim";
		pinctrl-names = "maxim_active";
		pinctrl-0 = <&maxim_active>;
		data-gpio = <&tlmm 146 0x00>;
		gpio-addr-set-out = <0xF192000>;
		gpio-addr-set-in = <0xF192000>;
		gpio-addr-level_high = <0xF192004>;
		gpio-addr-level_low = <0xF192004>;
		gpio-addr-data-in = <0xF192004>;
		gpio-addr-offset = <0x0>;

		gpio-set-out-val = <0x1bc3>;
		gpio-set-in-val = <0x19c3>;
		gpio_level_high_val = <0x3>;
		gpio_level_low_val = <0x0>;

		oplus,batt_info = /bits/ 8 <0x36 0x31 0x31 0x33 0x30 0x33 0x30 0x30 0x30 0x31 0x33 0x31>;

		oplus,ic_type = <OPLUS_CHG_IC_GAUGE>;
		oplus,ic_index = <1>;
	};
};

&qupv3_se4_i2c_pins {
	qupv3_se4_i2c_pulldown: qupv3_se4_i2c_pulldown {
		mux {
			pins = "gpio16", "gpio17";
			function = "gpio";
		};

		config {
			pins = "gpio16", "gpio17";
			drive-strength = <2>;
			bias-pull-down;
			output-low;
		};
	};

	qupv3_se4_i2c_pullup: qupv3_se4_i2c_pullup {
		mux {
			pins = "gpio16", "gpio17";
			function = "gpio";
		};

		config {
			pins = "gpio16", "gpio17";
			drive-strength = <2>;
			bias-pull-up;
			input-enable;
		};
	};
};

&qupv3_se13_i2c_pins {
	qupv3_se13_i2c_sda_active: qupv3_se13_i2c_sda_active {
		mux {
			pins = "gpio52";
			function = "qup1_se5_l0";
		};

		config {
			pins = "gpio52";
			drive-strength = <2>;
			bias-pull-up;
			qcom,i2c_pull; /* 2.2k Pull up */
		};
	};

	qupv3_se13_i2c_scl_active: qupv3_se13_i2c_scl_active {
		mux {
			pins = "gpio53";
			function = "qup1_se5_l1";
		};

		config {
			pins = "gpio53";
			drive-strength = <2>;
			bias-pull-up;
			qcom,i2c_pull; /* 2.2k Pull up */
		};
	};

	qupv3_se13_i2c_sleep: qupv3_se13_i2c_sleep {
		mux {
			pins = "gpio52", "gpio53";
			function = "gpio";
		};

		config {
			pins = "gpio52", "gpio53";
			drive-strength = <2>;
			bias-pull-up;
			qcom,i2c_pull; /* 2.2k Pull up */
		};
	};
};

&pmxr2230_gpios {
	usbtemp_l_gpio_default: usbtemp_l_gpio_default {
		pins = "gpio3"; //GPIO 3
		function = "normal"; //normal
		bias-high-impedance; //DISABLE GPIO3 for ADC
		bias-disable;
	};

	usbtemp_r_gpio_default: usbtemp_r_gpio_default {
		pins = "gpio4"; //GPIO 4
		function = "normal"; //normal
		bias-high-impedance; //DISABLE GPIO4 for ADC
		bias-disable;
	};
};

&pmk8550_gpios {
	subboard_temp_gpio_default: subboard_temp_gpio_default {
		pins = "gpio1"; /* GPIO 1 */
		function = "normal"; /* normal */
		bias-high-impedance; /* DISABLE GPIO1 for ADC*/
	};
};

&qupv3_se13_i2c {
	status = "okay";
	qcom,clk-freq-out = <400000>;
	pinctrl-names = "default", "sleep";
	pinctrl-0 = <&qupv3_se13_i2c_sda_active>, <&qupv3_se13_i2c_scl_active>;
	pinctrl-1 = <&qupv3_se13_i2c_sleep>;

	oplus_nu2112a: oplus,nu2112a@6E {
		status = "okay";
		compatible = "oplus,nu2112a";
		reg = <0x6E>;

		ocp_reg = <0x2E>;
		ovp_reg = <0x70>;

		oplus,use_vooc_phy;
		oplus,use_ufcs_phy;
		oplus,irq_gpio = <&tlmm 51 0x00>;
		pinctrl-names = "charging_inter_active", "charging_inter_sleep";
		pinctrl-0 = <&charging_inter_active>;
		pinctrl-1 = <&charging_inter_sleep>;

		oplus,ic_type = <OPLUS_CHG_IC_VPHY>;
		oplus,ic_index = <0>;
		oplus,vooc-version = <VOOC_VERSION_5_0>;

		oplus_spec,voocphy_dual_cp_support;
		oplus_spec,slave_cp_enable_thr = <1400>;		//2000-100mA
		oplus_spec,slave_cp_disable_thr_high = <1100>;//1500+100mA
		oplus_spec,voocphy_current_default = <73>;

		oplus_spec,svooc_cool_down_current_limit = <146 20 20 24 30 34 40 44 50 54 60 64 70 74>;
		oplus_spec,vooc_cool_down_current_limit = <73 20 20 24 30 34 40 44 50 54 60 64 70 74>;

		oplus_spec,vooc_multistep_initial_batt_temp = <1000>;
		oplus_spec,vooc_little_cool_temp = <160>;
		oplus_spec,vooc_little_cool_high_temp = <200>;
		oplus_spec,vooc_cool_temp = <120>;
		oplus_spec,vooc_little_cold_temp = <50>;
		oplus_spec,vooc_normal_low_temp = <350>;
		oplus_spec,vooc_strategy_normal_current = <146>;
		oplus_spec,vooc_normal_to_little_cool_current = <100>;
		oplus_spec,vooc_over_high_temp = <510>;
		oplus_spec,vooc_low_temp = <0>;

		oplus_spec,vooc_high_temp = <500>;
		oplus_spec,vooc_low_soc = <0>;
		oplus_spec,vooc_high_soc = <90>;
		oplus_spec,vooc_normal_high_temp = <440>;
		oplus_spec,vooc_warm_vol_thr = <4000>;
		oplus_spec,vooc_warm_soc_thr = <50>;

		oplus_spec,vooc_strategy1_batt_high_temp0 = <385>;
		oplus_spec,vooc_strategy1_batt_high_temp1 = <395>;
		oplus_spec,vooc_strategy1_batt_high_temp2 = <420>;
		oplus_spec,vooc_strategy1_batt_low_temp2 = <410>;
		oplus_spec,vooc_strategy1_batt_low_temp1 = <385>;
		oplus_spec,vooc_strategy1_batt_low_temp0 = <375>;

		oplus_spec,vooc_strategy1_high_current0 = <80>;
		oplus_spec,vooc_strategy1_high_current1 = <61>;
		oplus_spec,vooc_strategy1_high_current2 = <40>;
		oplus_spec,vooc_strategy1_low_current2 = <40>;
		oplus_spec,vooc_strategy1_low_current1 = <61>;
		oplus_spec,vooc_strategy1_low_current0 = <80>;

		oplus_spec,voocphy_freq_mincore = <925000>;
		oplus_spec,voocphy_freq_midcore = <1918000>;
		oplus_spec,voocphy_freq_maxcore = <1918000>;
		oplus_spec,voocphy_current_change_timeout = <100>;
		oplus_spec,copycat_vooc_support;
		oplus_spec,copycat_vooc_accuracy_value = <105>;

		oplus_spec,voocphy_ibat_over_current = <16000>;
		oplus_spec,voocphy_svooc_cp_max_ibus = <4500>;
		oplus_spec,voocphy_vooc_cp_max_ibus = <4500>;
		oplus_spec,voocphy_cp_max_ibus = <4500>;

		oplus_spec,vooc_little_cold_full_voltage = <4570>;
		oplus_spec,vooc_cool_full_voltage = <4570>;
		oplus_spec,vooc_little_cool_full_voltage = <4570>;
		oplus_spec,vooc_little_cool_high_full_voltage = <4570>;
		oplus_spec,vooc_warm_full_voltage = <4130>;
		oplus_spec,vooc_1time_full_voltage = <4580>;
		oplus_spec,vooc_ntime_full_voltage = <4570>;
		oplus_spec,low_curr_full_t1 = <120>;
		oplus_spec,low_curr_full_t2 = <350>;
		oplus_spec,low_curr_full_t3 = <430>;
		/*oplus_spec,range1_low_curr_full = <1250 4570
						1150 4565
						1050 4550
						 950 4540
						 850 4530>;
		oplus_spec,range2_low_curr_full = <1650 4570
						1550 4565
						1550 4550
						1350 4540
						1250 4530>; */

		svooc_batt_sys_curve = <0 1 0 1 0 0 0	// 4000mA
					1 1 1 1 0 0 0	// 4604mV
					0 0 1 1 0 1 0	// 2600mA
					1 1 1 1 0 0 0	// 4604mV
					0 0 0 1 0 1 1	// 1100mA
					1 1 1 1 0 0 0>;	// 4604mV

		vooc_batt_sys_curve =  <0 1 0 1 0 0 0	// 4000mA
					1 1 1 1 0 0 0	// 4604mV
					0 0 1 1 0 1 0	// 2600mA
					1 1 1 1 0 0 0	// 4604mV
					0 0 0 1 0 1 1	// 1100mA
					1 1 1 1 0 0 0>;	// 4604mV

		oplus_spec,soc_range = <0 20 35 55 75 85 95>;

		svooc_lcf_strategy {
			oplus,temp_type = <OPLUS_STRATEGY_USE_SHELL_TEMP>;
			oplus,temp_range = <0 50 120 160 200 350 430>;

			strategy_temp_range_curves {
				strategy_temp_range_t0 =	<500 4470 0
								 450 4460 0
								 400 4450 0
								 350 4440 0
								 300 4430 1>;
				strategy_temp_range_t1 =	<700 4470 0
								 650 4460 0
								 600 4450 0
								 550 4440 0
								 500 4430 1>;
				strategy_temp_range_t2 =	<950 4570 0
								 850 4565 0
								 750 4550 0
								 650 4540 0
								 550 4530 1>;
				strategy_temp_range_t3 =	<1250 4570 0
								 1150 4565 0
								 1050 4550 0
								 950 4540 0
								 850 4530 1>;
				strategy_temp_range_t4 =	<1250 4570 0
								 1150 4565 0
								 1050 4550 0
								 950 4540 0
								 850 4530 1>;
				strategy_temp_range_t5 =	<1650 4570 0
								 1550 4565 0
								 1450 4550 0
								 1350 4540 0
								 1250 4530 1>;
			};
		};
		svooc_charge_strategy {
			strategy_soc_0_to_50 {  /* 0 ~ 20 */
				strategy_temp_little_cold =	<4150 35 0 0 0
								 4150 30 0 0 0
								 4460 29 0 0 0
								 4460 25 0 0 0
								 4460 23 0 0 0
								 4460 20 0 0 0
								 4460 15 0 0 0
								 4470 10 1 0 0>;
				strategy_temp_cool =		<4150 44 0 0 0
								 4150 40 0 0 0
								 4460 35 0 0 0
								 4460 30 0 0 0
								 4460 25 0 0 0
								 4460 23 0 0 0
								 4460 20 0 0 0
								 4460 15 0 0 0
								 4470 10 1 0 0>;
				strategy_temp_little_cool =	<4150 73 0 60 0
								 4510 59 0 360 0
								 4510 55 0 480 0
								 4510 50 0 480 0
								 4560 44 0 480 0
								 4560 40 0 480 0
								 4560 35 0 0 0
								 4560 30 0 0 0
								 4560 25 0 0 0
								 4560 20 0 0 0
								 4560 15 0 0 0
								 4570 10 1 0 0>;
				strategy_temp_little_cool_high = <4250 73 0 60 0
								 4280 61 0 360 0
								 4510 56 0 480 0
								 4510 50 0 480 0
								 4560 41 0 480 0
								 4560 40 0 480 0
								 4560 35 0 0 0
								 4560 30 0 0 0
								 4560 25 0 0 0
								 4560 20 0 0 0
								 4560 15 0 0 0
								 4570 10 1 0 0>;
				strategy_temp_normal_low =	<4250 73 0 60 0
								 4280 61 0 360 0
								 4510 56 0 480 0
								 4510 50 0 480 0
								 4560 41 0 480 0
								 4560 40 0 480 0
								 4560 35 0 0 0
								 4560 30 0 0 0
								 4560 25 0 0 0
								 4560 20 0 0 0
								 4560 15 0 0 0
								 4570 10 1 0 0>;
				strategy_temp_normal_high =	<4250 73 0 60 0
								 4280 61 0 360 0
								 4510 56 0 480 0
								 4510 50 0 480 0
								 4560 41 0 480 0
								 4560 40 0 480 0
								 4560 35 0 0 0
								 4560 30 0 0 0
								 4560 25 0 0 0
								 4560 20 0 0 0
								 4560 15 0 0 0
								 4570 10 1 0 0>;
				strategy_temp_warm =		<4130 10 1 0 0>;
			};

			strategy_soc_0_to_50_mid { /* 21 ~ 35 */
				strategy_temp_little_cold =	<4150 35 0 0 0
								 4150 30 0 0 0
								 4460 29 0 0 0
								 4460 25 0 0 0
								 4460 23 0 0 0
								 4460 20 0 0 0
								 4460 15 0 0 0
								 4470 10 1 0 0>;
				strategy_temp_cool =		<4150 44 0 0 0
								 4150 40 0 0 0
								 4460 35 0 0 0
								 4460 30 0 0 0
								 4460 25 0 0 0
								 4460 23 0 0 0
								 4460 20 0 0 0
								 4460 15 0 0 0
								 4470 10 1 0 0>;
				strategy_temp_little_cool =	<4150 73 0 60 0
								 4510 59 0 360 0
								 4510 55 0 480 0
								 4510 50 0 480 0
								 4560 44 0 480 0
								 4560 40 0 480 0
								 4560 35 0 0 0
								 4560 30 0 0 0
								 4560 25 0 0 0
								 4560 20 0 0 0
								 4560 15 0 0 0
								 4570 10 1 0 0>;
				strategy_temp_little_cool_high = <4250 73 0 60 0
								 4280 61 0 360 0
								 4510 56 0 480 0
								 4510 50 0 480 0
								 4560 41 0 480 0
								 4560 40 0 480 0
								 4560 35 0 0 0
								 4560 30 0 0 0
								 4560 25 0 0 0
								 4560 20 0 0 0
								 4560 15 0 0 0
								 4570 10 1 0 0>;
				strategy_temp_normal_low =	<4250 73 0 60 0
								 4280 61 0 360 0
								 4510 56 0 480 0
								 4510 50 0 480 0
								 4560 41 0 480 0
								 4560 40 0 480 0
								 4560 35 0 0 0
								 4560 30 0 0 0
								 4560 25 0 0 0
								 4560 20 0 0 0
								 4560 15 0 0 0
								 4570 10 1 0 0>;
				strategy_temp_normal_high =	<4250 73 0 60 0
								 4280 61 0 360 0
								 4510 56 0 480 0
								 4510 50 0 480 0
								 4560 41 0 480 0
								 4560 40 0 480 0
								 4560 35 0 0 0
								 4560 30 0 0 0
								 4560 25 0 0 0
								 4560 20 0 0 0
								 4560 15 0 0 0
								 4570 10 1 0 0>;
				strategy_temp_warm =		<4130 10 1 0 0>;
			};

			strategy_soc_0_to_50_high { /* 36 ~ 55 */
				strategy_temp_little_cold =	<4460 20 0 0 0
								 4460 15 0 0 0
								 4470 10 1 0 0>;
				strategy_temp_cool =	<4460 25 0 0 0
								 4460 23 0 0 0
								 4460 20 0 0 0
								 4460 15 0 0 0
								 4470 10 1 0 0>;
				strategy_temp_little_cool =	<4560 40 0 60 0
								 4560 35 0 360 0
								 4560 30 0 480 0
								 4560 25 0 480 0
								 4560 20 0 480 0
								 4560 15 0 480 0
								 4570 10 1 0 0>;
				strategy_temp_little_cool_high = <4250 73 0 60 0
								 4280 61 0 360 0
								 4510 56 0 480 0
								 4510 50 0 480 0
								 4560 41 0 480 0
								 4560 40 0 480 0
								 4560 35 0 0 0
								 4560 30 0 0 0
								 4560 25 0 0 0
								 4560 20 0 0 0
								 4560 15 0 0 0
								 4570 10 1 0 0>;
				strategy_temp_normal_low =	<4250 73 0 60 0
								 4280 61 0 360 0
								 4510 56 0 480 0
								 4510 50 0 480 0
								 4560 41 0 480 0
								 4560 40 0 480 0
								 4560 35 0 0 0
								 4560 30 0 0 0
								 4560 25 0 0 0
								 4560 20 0 0 0
								 4560 15 0 0 0
								 4570 10 1 0 0>;
				strategy_temp_normal_high =	<4250 73 0 60 0
								 4280 61 0 360 0
								 4510 56 0 480 0
								 4510 50 0 480 0
								 4560 41 0 480 0
								 4560 40 0 480 0
								 4560 35 0 0 0
								 4560 30 0 0 0
								 4560 25 0 0 0
								 4560 20 0 0 0
								 4560 15 0 0 0
								 4570 10 1 0 0>;
				strategy_temp_warm =		<4130 10 1 0 0>;
			};

			strategy_soc_50_to_75 { /* 56 ~ 75 */
				strategy_temp_little_cold =	<4460 15 0 0 0
								 4470 10 1 0 0>;
				strategy_temp_cool =		<4460 15 0 0 0
								 4470 10 1 0 0>;
				strategy_temp_little_cool =	<4560 20 0 0 0
								 4560 15 0 0 0
								 4570 10 1 0 0>;
				strategy_temp_little_cool_high = <4560 25 0 0 0
								 4560 20 0 0 0
								 4560 15 0 0 0
								 4570 10 1 0 0>;
				strategy_temp_normal_low =	<4560 25 0 0 0
								 4560 20 0 0 0
								 4560 15 0 0 0
								 4570 10 1 0 0>;
				strategy_temp_normal_high =	<4560 30 0 0 0
								 4560 25 0 0 0
								 4560 20 0 0 0
								 4560 15 0 0 0
								 4570 10 1 0 0>;
				strategy_temp_warm = 		<4130 10 1 0 0>;
			};

			strategy_soc_75_to_85 { /* 76 ~ 85 */
				strategy_temp_little_cold =	<4470 10 1 0 0>;
				strategy_temp_cool =		<4470 10 1 0 0>;
				strategy_temp_little_cool =	<4560 15 0 0 0
								 4570 10 1 0 0>;
				strategy_temp_little_cool_high = <4560 15 0 0 0
								 4570 10 1 0 0>;
				strategy_temp_normal_low =	<4560 15 0 0 0
								 4570 10 1 0 0>;
				strategy_temp_normal_high =	<4560 20 0 0 0
								 4560 15 0 0 0
								 4570 10 1 0 0>;
				strategy_temp_warm = 		<4130 10 1 0 0>;
			};

			strategy_soc_85_to_90 { /* 86 ~ 95 */
				strategy_temp_little_cold =	<4470 10 1 0 0>;
				strategy_temp_cool =		<4470 10 1 0 0>;
				strategy_temp_little_cool =	<4570 10 1 0 0>;
				strategy_temp_little_cool_high = <4570 10 1 0 0>;
				strategy_temp_normal_low =	<4570 10 1 0 0>;
				strategy_temp_normal_high =	<4570 10 1 0 0>;
				strategy_temp_warm = 		<4130 10 1 0 0>;
			};
		};

		vooc_charge_strategy {
			strategy_soc_0_to_50 {
				strategy_temp_little_cold =	<4150 60 0 0 0
								 4460 58 0 0 0
								 4460 50 0 0 0
								 4460 46 0 0 0
								 4460 40 0 0 0
								 4460 30 0 0 0
								 4470 20 1 0 0>;
				strategy_temp_cool =		<4460 60 0 0 0
								 4460 50 0 0 0
								 4460 46 0 0 0
								 4460 40 0 0 0
								 4460 30 0 0 0
								 4470 20 1 0 0>;
				strategy_temp_little_cool =	<4560 60 0 0 0
								 4560 50 0 0 0
								 4560 40 0 0 0
								 4560 30 0 0 0
								 4570 20 1 0 0>;
				strategy_temp_little_cool_high = <4560 60 0 0 0
								 4560 50 0 0 0
								 4560 40 0 0 0
								 4560 30 0 0 0
								 4570 20 1 0 0>;
				strategy_temp_normal_low =	<4560 60 0 0 0
								 4560 50 0 0 0
								 4560 40 0 0 0
								 4560 30 0 0 0
								 4570 20 1 0 0>;
				strategy_temp_normal_high =	<4560 60 0 0 0
								 4560 50 0 0 0
								 4560 40 0 0 0
								 4560 30 0 0 0
								 4570 20 1 0 0>;
				strategy_temp_warm =		<4130 20 1 0 0>;
			};

			strategy_soc_0_to_50_mid {
				strategy_temp_little_cold =	<4150 60 0 0 0
								 4460 58 0 0 0
								 4460 50 0 0 0
								 4460 46 0 0 0
								 4460 40 0 0 0
								 4460 30 0 0 0
								 4470 20 1 0 0>;
				strategy_temp_cool =		<4460 60 0 0 0
								 4460 50 0 0 0
								 4460 46 0 0 0
								 4460 40 0 0 0
								 4460 30 0 0 0
								 4470 20 1 0 0>;
				strategy_temp_little_cool =	<4560 60 0 0 0
								 4560 50 0 0 0
								 4560 40 0 0 0
								 4560 30 0 0 0
								 4570 20 1 0 0>;
				strategy_temp_little_cool_high = <4560 60 0 0 0
								 4560 50 0 0 0
								 4560 40 0 0 0
								 4560 30 0 0 0
								 4570 20 1 0 0>;
				strategy_temp_normal_low =	<4560 60 0 0 0
								 4560 50 0 0 0
								 4560 40 0 0 0
								 4560 30 0 0 0
								 4570 20 1 0 0>;
				strategy_temp_normal_high =	<4560 60 0 0 0
								 4560 50 0 0 0
								 4560 40 0 0 0
								 4560 30 0 0 0
								 4570 20 1 0 0>;
				strategy_temp_warm =		<4130 20 1 0 0>;
			};

			strategy_soc_0_to_50_high {
				strategy_temp_little_cold =	<4460 40 0 0 0
								 4460 30 0 0 0
								 4470 20 1 0 0>;
				strategy_temp_cool =		<4460 50 0 0 0
								 4460 46 0 0 0
								 4460 40 0 0 0
								 4460 30 0 0 0
								 4470 20 1 0 0>;
				strategy_temp_little_cool =	<4560 60 0 0 0
								 4560 50 0 0 0
								 4560 40 0 0 0
								 4560 30 0 0 0
								 4570 20 1 0 0>;
				strategy_temp_little_cool_high = <4560 60 0 0 0
								 4560 50 0 0 0
								 4560 40 0 0 0
								 4560 30 0 0 0
								 4570 20 1 0 0>;
				strategy_temp_normal_low =	<4560 60 0 0 0
								 4560 50 0 0 0
								 4560 40 0 0 0
								 4560 30 0 0 0
								 4570 20 1 0 0>;
				strategy_temp_normal_high =	<4560 60 0 0 0
								 4560 50 0 0 0
								 4560 40 0 0 0
								 4560 30 0 0 0
								 4570 20 1 0 0>;
				strategy_temp_warm =		<4130 20 1 0 0>;
			};

			strategy_soc_50_to_75 {
				strategy_temp_little_cold =	<4460 30 0 0 0
								 4470 20 1 0 0>;
				strategy_temp_cool =		<4460 30 0 0 0
								 4470 20 1 0 0>;
				strategy_temp_little_cool =	<4560 40 0 0 0
								 4560 30 0 0 0
								 4570 20 1 0 0>;
				strategy_temp_little_cool_high = <4560 50 0 0 0
								 4560 40 0 0 0
								 4560 30 0 0 0
								 4570 20 1 0 0>;
				strategy_temp_normal_low =	<4560 50 0 0 0
								 4560 40 0 0 0
								 4560 30 0 0 0
								 4570 20 1 0 0>;
				strategy_temp_normal_high =	<4560 60 0 0 0
								 4560 50 0 0 0
								 4560 40 0 0 0
								 4560 30 0 0 0
								 4570 20 1 0 0>;
				strategy_temp_warm =		<4130 20 1 0 0>;
			};

			strategy_soc_75_to_85 {
				strategy_temp_little_cold =	<4470 20 1 0 0>;
				strategy_temp_cool =		<4470 20 1 0 0>;
				strategy_temp_little_cool =	<4560 30 0 0 0
								 4570 20 1 0 0>;
				strategy_temp_little_cool_high = <4560 30 0 0 0
								 4570 20 1 0 0>;
				strategy_temp_normal_low =	<4560 30 0 0 0
								 4570 20 1 0 0>;
				strategy_temp_normal_high =	<4560 40 0 0 0
								 4560 30 0 0 0
								 4570 20 1 0 0>;
				strategy_temp_warm = 		<4130 20 1 0 0>;
			};

			strategy_soc_85_to_90 {
				strategy_temp_little_cold =	<4470 20 1 0 0>;
				strategy_temp_cool =		<4470 20 1 0 0>;
				strategy_temp_little_cool =	<4570 20 1 0 0>;
				strategy_temp_little_cool_high = <4570 20 1 0 0>;
				strategy_temp_normal_low =	<4570 20 1 0 0>;
				strategy_temp_normal_high =	<4570 20 1 0 0>;
				strategy_temp_warm = 		<4130 20 1 0 0>;
			};
		};

		oplus_nu2112a_cp: oplus,nu2112a_cp {
			oplus,ic_type = <OPLUS_CHG_IC_CP>;
			oplus,ic_index = <0>;
		};
	};
};

&qupv3_se8_i2c {
	status = "okay";
	clock-frequency = <400000>;
	oplus_nu2112a_slave: nu2112a-charger-slave@6E{
		status = "okay";
		compatible = "oplus,nu2112a-slave";
		reg = <0x6E>;

		ocp_reg = <0x2E>;
		ovp_reg = <0x70>;
		oplus,irq_gpio = <&tlmm 128 0x00>;
		oplus_nu2112a_slave_cp: oplus,nu2112a_slave_cp {
			oplus,ic_type = <OPLUS_CHG_IC_CP>;
			oplus,ic_index = <1>;
		};
	};
};

&soc {
	oplus_ufcs_impedance_check: oplus,ufcs_impedance_check {
		compatible = "oplus,impedance_check";

		oplus,impedance_unit {
			oplus_ufcs_impedance_unit: oplus,ufcs_impedance_unit {
				uint_name = "ufcs";
				default_curr_ma = <3000>;
				impedance_node = <&ufcs_input_impedance>;
			};
		};
	};
};

&soc {
	oplus_cpa: oplus,cpa {
		compatible = "oplus,cpa";
		oplus,protocol_list = <CHG_PROTOCOL_UFCS 33
					   CHG_PROTOCOL_PD 18
				       CHG_PROTOCOL_VOOC 80
				       CHG_PROTOCOL_QC 18>;
		oplus,default_protocol_list = <CHG_PROTOCOL_UFCS
						   CHG_PROTOCOL_PD
					       CHG_PROTOCOL_VOOC>;
	};
};
